# nrf9230_engb_cellcore register map
Vendor: Nordic Semiconductor; Series: nRF92; File version: 1
CPU: CM33 r0p4, little endian, MPU, FPU, 3 interrupt priority bits, 480 interrupts, 8 SAU regions
Registers are 32-bit, read-write, reset 0x0 unless marked. A register's access mark holds for its fields unless they carry their own. Offsets are from the block's base; [hi:lo] are bit positions; lines under a group give offsets from that group; {n}, {i} and the like mark numbered series; 'fields as' and 'values as' point back to an identical list.

## GLOBAL_CAN120_NS — Controller Area Network 0
Base 0x4F8D8000
Same registers: GLOBAL_CAN121_NS 0x4F8DB000, GLOBAL_CAN120_S 0x5F8D8000, GLOBAL_CAN121_S 0x5F8DB000
0x00 TASKS_START wo — Start the CAN peripheral.
  [0] TASKS_START
    1=Trigger task
0x04 TASKS_STOPREQ wo — Request to stop the CAN peripheral
  [0] TASKS_STOPREQ
    1=Trigger task
0x08 TASKS_STOP wo — Stop the CAN peripheral
  [0] TASKS_STOP
    1=Trigger task
{0x100+4i} EVENTS_CORE[{i}] (i=0..1) — Description collection: Event indicating that interrupt n triggered at CAN core
  [0] EVENTS_CORE — Event indicating that interrupt n triggered at CAN core
    0=NotGenerated (Event not generated); 1=Generated (Event generated)
0x108 EVENTS_DMU — Event indicating that interrupt triggered at CAN DMU
  [0] EVENTS_DMU
    values as EVENTS_CORE[0].EVENTS_CORE
0x10C EVENTS_DMA — Event indicating that interrupt triggered at CAN DMA
  [0] EVENTS_DMA
    values as EVENTS_CORE[0].EVENTS_CORE
0x110 EVENTS_READYFORSTOP — Event indicating that the CAN is ready to be stopped
  [0] EVENTS_READYFORSTOP
    values as EVENTS_CORE[0].EVENTS_CORE
0x200 SHORTS — Shortcuts between local events and tasks
  [0] READYFORSTOP_STOP — Shortcut between event READYFORSTOP and task STOP
    0=Disabled (Disable shortcut); 1=Enabled (Enable shortcut)
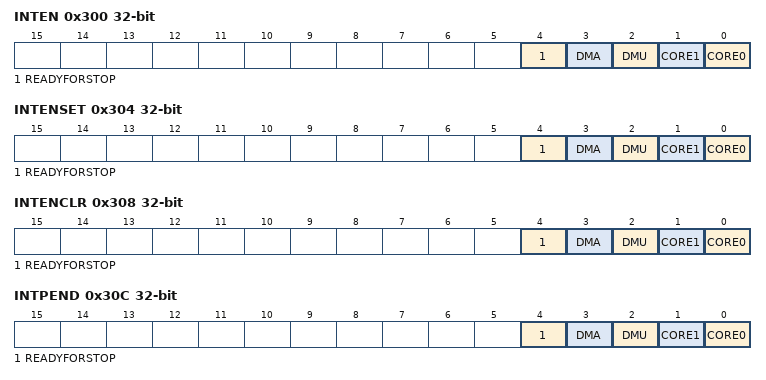
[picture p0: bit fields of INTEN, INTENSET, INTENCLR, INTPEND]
0x300 INTEN — Enable or disable interrupt
  [all] fields
    0=Disabled; 1=Enabled
  [4] READYFORSTOP — Enable or disable interrupt for event READYFORSTOP
  [3] DMA — Enable or disable interrupt for event DMA
  [2] DMU — Enable or disable interrupt for event DMU
  [1] CORE1 — Enable or disable interrupt for event CORE[1]
  [0] CORE0 — Enable or disable interrupt for event CORE[0]
0x304 INTENSET — Enable interrupt
  [all] fields
    on read: 0=Disabled (Read: Disabled); 1=Enabled (Read: Enabled) | on write: 1=Set (Enable)
  [4] READYFORSTOP — Write '1' to enable interrupt for event READYFORSTOP
  [3] DMA — Write '1' to enable interrupt for event DMA
  [2] DMU — Write '1' to enable interrupt for event DMU
  [1] CORE1 — Write '1' to enable interrupt for event CORE[1]
  [0] CORE0 — Write '1' to enable interrupt for event CORE[0]
0x308 INTENCLR — Disable interrupt
  [all] fields
    on read: 0=Disabled (Read: Disabled); 1=Enabled (Read: Enabled) | on write: 1=Clear (Disable)
  [4] READYFORSTOP — Write '1' to disable interrupt for event READYFORSTOP
  [3] DMA — Write '1' to disable interrupt for event DMA
  [2] DMU — Write '1' to disable interrupt for event DMU
  [1] CORE1 — Write '1' to disable interrupt for event CORE[1]
  [0] CORE0 — Write '1' to disable interrupt for event CORE[0]
0x30C INTPEND ro — Pending interrupts
  [all] fields
    on read: 0=NotPending (Read: Not pending); 1=Pending (Read: Pending)
  [4] READYFORSTOP — Read pending status of interrupt for event READYFORSTOP
  [3] DMA — Read pending status of interrupt for event DMA
  [2] DMU — Read pending status of interrupt for event DMU
  [1] CORE1 — Read pending status of interrupt for event CORE[1]
  [0] CORE0 — Read pending status of interrupt for event CORE[0]
0x400 MISC — Register for controlling miscellaneous functions and features of the M_CAN.
  [0] DISMORD — Disable modification on read

## GLOBAL_RAMC122_NS — RAM Controller 0
Base 0x4F8DA000
Same registers: GLOBAL_RAMC123_NS 0x4F8DD000, GLOBAL_RAMC122_S 0x5F8DA000, GLOBAL_RAMC123_S 0x5F8DD000
0x500 WAITSTATES — Waitstates for read operations.
  [0] WAITSTATES — Number of waitstates for a read from the RAM.

## GLOBAL_EGU130_NS — Event generator unit 0
Base 0x4F92D000
Same registers: GLOBAL_EGU130_S 0x5F92D000
{0x0+4i} TASKS_TRIGGER[{i}] (i=0..15) wo — Description collection: Trigger n for triggering the corresponding TRIGGERED[n] event
  [0] TASKS_TRIGGER — Trigger n for triggering the corresponding TRIGGERED[n] event
    1=Trigger task
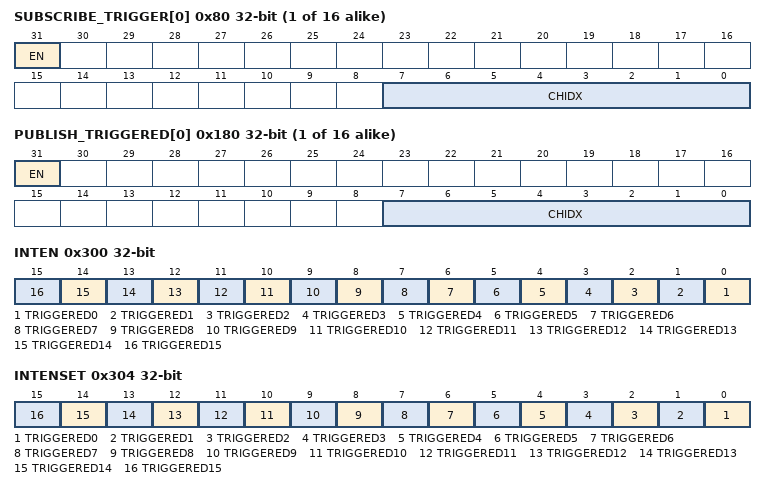
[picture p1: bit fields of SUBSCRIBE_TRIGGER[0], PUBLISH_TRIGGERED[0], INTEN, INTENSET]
{0x80+4i} SUBSCRIBE_TRIGGER[{i}] (i=0..15) — Description collection: Subscribe configuration for task TRIGGER[n]
  [31] EN
    0=Disabled (Disable subscription); 1=Enabled (Enable subscription)
  [7:0] CHIDX — DPPI channel that task TRIGGER[n] will subscribe to
{0x100+4i} EVENTS_TRIGGERED[{i}] (i=0..15) — Description collection: Event number n generated by triggering the corresponding TRIGGER[n] task
  [0] EVENTS_TRIGGERED — Event number n generated by triggering the corresponding TRIGGER[n] task
    0=NotGenerated (Event not generated); 1=Generated (Event generated)
{0x180+4i} PUBLISH_TRIGGERED[{i}] (i=0..15) — Description collection: Publish configuration for event TRIGGERED[n]
  [31] EN
    0=Disabled (Disable publishing); 1=Enabled (Enable publishing)
  [7:0] CHIDX — DPPI channel that event TRIGGERED[n] will publish to
0x300 INTEN — Enable or disable interrupt
  [all] fields
    0=Disabled; 1=Enabled
  [n] TRIGGERED{n} (n=0..15) — Enable or disable interrupt for event TRIGGERED[{n}]
0x304 INTENSET — Enable interrupt
  [all] fields
    on read: 0=Disabled (Read: Disabled); 1=Enabled (Read: Enabled) | on write: 1=Set (Enable)
  [n] TRIGGERED{n} (n=0..15) — Write '1' to enable interrupt for event TRIGGERED[{n}]
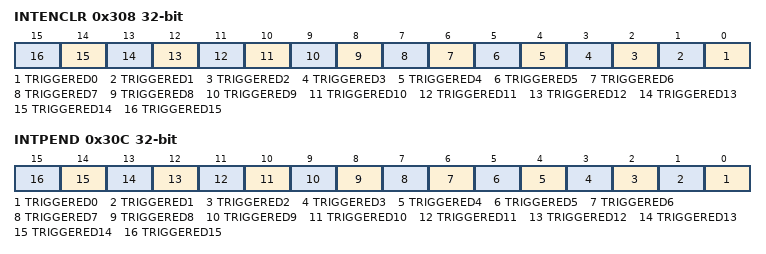
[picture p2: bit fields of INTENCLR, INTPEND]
0x308 INTENCLR — Disable interrupt
  [all] fields
    on read: 0=Disabled (Read: Disabled); 1=Enabled (Read: Enabled) | on write: 1=Clear (Disable)
  [n] TRIGGERED{n} (n=0..15) — Write '1' to disable interrupt for event TRIGGERED[{n}]
0x30C INTPEND ro — Pending interrupts
  [all] fields
    on read: 0=NotPending (Read: Not pending); 1=Pending (Read: Pending)
  [n] TRIGGERED{n} (n=0..15) — Read pending status of interrupt for event TRIGGERED[{n}]

## GLOBAL_GPIOINTERNAL_NS — GPIO Internal 0
Base 0x4F939E00
Same registers: GLOBAL_GPIOINTERNAL_S 0x5F939E00
0x40 LATCHCLRWAITCNT reset 0x2 — Select the number of wait cycles inserted on the bus when a LATCH register is cleared.
  [1:0] LATCHCLRWAITCNT
0x44 FORCELDETECTLOWCNT reset 0x8 — Select the number of cycles that LDETECT is forced low after clearing a LATCH register.
  [3:0] FORCELDETECTLOWCNT
0x48 RESET — Reset all GPIO registers.
  [0] RESET
    1=RESET (Trigger reset); 0=NA (No effect)
0x4C SENSECONFIGCHANGECNT reset 0x3 — Selects the number of cycles before the SENSE configuration takes effect when it is changed. Setting this register lower than the reset value can lead to unwanted LATCH set when SENSE and INPUT fields (PIN[n].CNF) are changed simultaneously.
  [2:0] SENSECONFIGCHANGECNT — Selects the number of cycles before the SENSE configuration takes effect when it is changed.
0x160 PCGC group — Unspecified
  0x00 TURNOFFAUTOCLOCKSOURCEREQ ro — No functionality
  {0x20+4j} PENALTY[{j}] (j=0..4) ro — Description collection: Penalty level for power/clock pair n
    [7:0] PENALTY — Penalty level
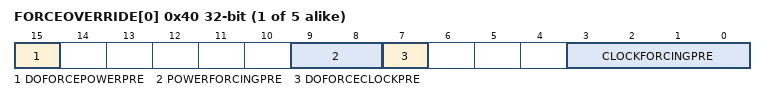
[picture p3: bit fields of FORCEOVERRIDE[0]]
  {0x40+4j} FORCEOVERRIDE[{j}] (j=0..4) ro — Description collection: Force override of power/clock pair n
    [15] DOFORCEPOWERPRE, [9:8] POWERFORCINGPRE, [7] DOFORCECLOCKPRE, [3:0] CLOCKFORCINGPRE
